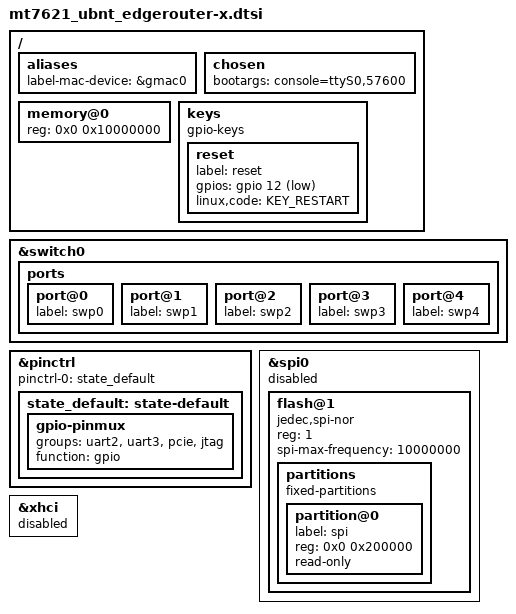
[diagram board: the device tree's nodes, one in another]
/dts-v1/;

#include "mt7621-upstream.dtsi"

#include <dt-bindings/gpio/gpio.h>
#include <dt-bindings/input/input.h>

/ {
	aliases {
		label-mac-device = &gmac0;
	};

	chosen {
		bootargs = "console=ttyS0,57600";
	};

	memory@0 {
		device_type = "memory";
		reg = <0x0 0x10000000>;
	};

	keys {
		compatible = "gpio-keys";

		reset {
			label = "reset";
			gpios = <&gpio 12 GPIO_ACTIVE_LOW>;
			linux,code = <KEY_RESTART>;
		};
	};
};

&switch0 {
	ports {
		port@0 {
			status = "okay";
			label = "swp0";
		};

		port@1 {
			status = "okay";
			label = "swp1";
		};

		port@2 {
			status = "okay";
			label = "swp2";
		};

		port@3 {
			status = "okay";
			label = "swp3";
		};

		port@4 {
			status = "okay";
			label = "swp4";
		};
	};
};

&pinctrl {
	pinctrl-names = "default";
	pinctrl-0 = <&state_default>;

	state_default: state-default {
		gpio-pinmux {
			groups = "uart2", "uart3", "pcie", "jtag";
			function = "gpio";
		};
	};
};

&spi0 {
	/*
	 * This board has 2Mb spi flash soldered in and visible
	 * from manufacturer's firmware.
	 * But this SoC shares spi and nand pins,
	 * and current driver doesn't handle this sharing well
	 */
	status = "disabled";

	flash@1 {
		compatible = "jedec,spi-nor";
		reg = <1>;
		spi-max-frequency = <10000000>;

		partitions {
			compatible = "fixed-partitions";
			#address-cells = <1>;
			#size-cells = <1>;

			partition@0 {
				label = "spi";
				reg = <0x0 0x200000>;
				read-only;
			};
		};
	};
};

&xhci {
	status = "disabled";
};
